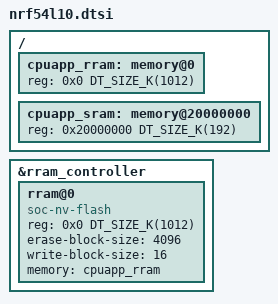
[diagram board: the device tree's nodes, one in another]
/*
 * Copyright (c) 2024 Nordic Semiconductor ASA
 *
 * SPDX-License-Identifier: Apache-2.0
 */

#include "nrf54l_05_10_15.dtsi"

/ {
	cpuapp_rram: memory@0 {
		device_type = "memory";
		reg = <0x0 DT_SIZE_K(1012)>;
		#address-cells = <1>;
		#size-cells = <1>;
		ranges = <0x0 0x0 DT_SIZE_K(1012)>;
	};

	cpuapp_sram: memory@20000000 {
		device_type = "memory";
		reg = <0x20000000 DT_SIZE_K(192)>;
		#address-cells = <1>;
		#size-cells = <1>;
		ranges = <0x0 0x20000000 DT_SIZE_K(192)>;
	};
};

&rram_controller {
	rram@0 {
		compatible = "soc-nv-flash";
		reg = <0x0 DT_SIZE_K(1012)>;
		erase-block-size = <4096>;
		write-block-size = <16>;
		memory = <&cpuapp_rram>;
	};
};
